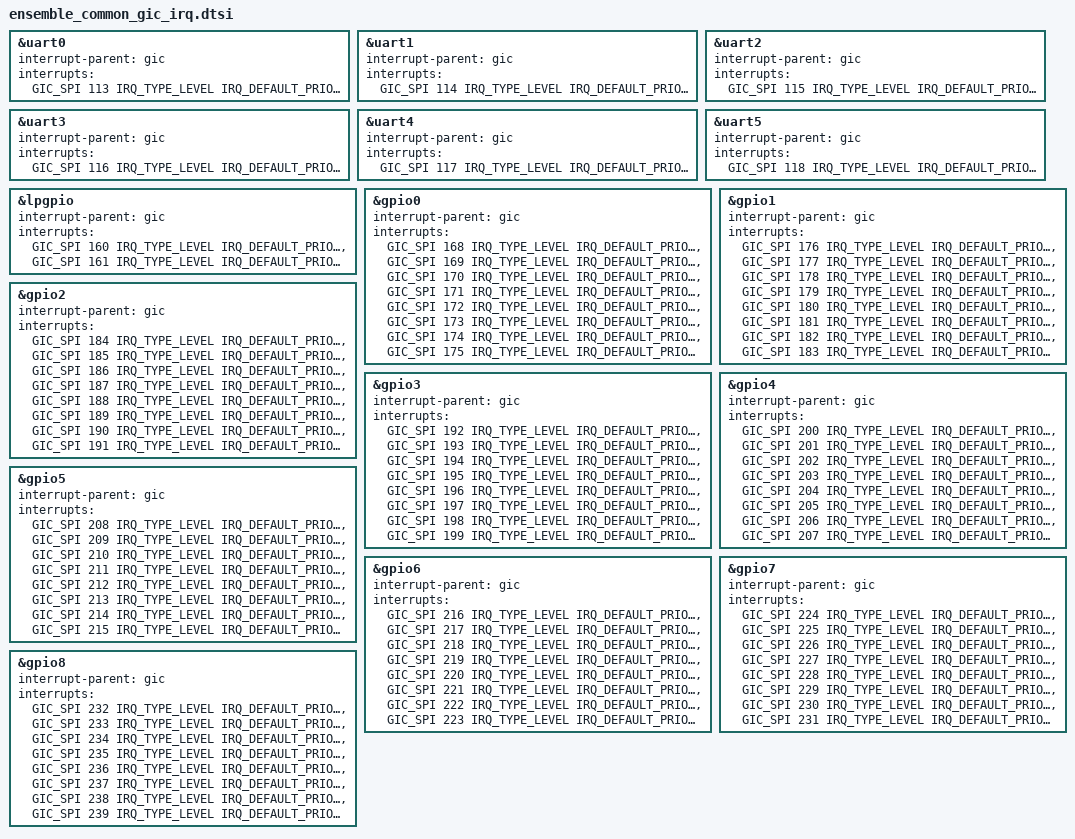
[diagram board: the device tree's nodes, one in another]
/*
 * SPDX-FileCopyrightText: Copyright Alif Semiconductor
 * SPDX-License-Identifier: Apache-2.0
 */

/*
 * GIC interrupt routing for peripherals common to all Ensemble SoCs
 * (the bottom resource layer; see ensemble_common.dtsi). Included by the
 * per-SoC <soc>_gic_irq.dtsi.
 */

#include <zephyr/dt-bindings/interrupt-controller/arm-gic.h>

&uart0 {
	interrupt-parent = <&gic>;
	interrupts = <GIC_SPI 113 IRQ_TYPE_LEVEL IRQ_DEFAULT_PRIORITY>;
};

&uart1 {
	interrupt-parent = <&gic>;
	interrupts = <GIC_SPI 114 IRQ_TYPE_LEVEL IRQ_DEFAULT_PRIORITY>;
};

&uart2 {
	interrupt-parent = <&gic>;
	interrupts = <GIC_SPI 115 IRQ_TYPE_LEVEL IRQ_DEFAULT_PRIORITY>;
};

&uart3 {
	interrupt-parent = <&gic>;
	interrupts = <GIC_SPI 116 IRQ_TYPE_LEVEL IRQ_DEFAULT_PRIORITY>;
};

&uart4 {
	interrupt-parent = <&gic>;
	interrupts = <GIC_SPI 117 IRQ_TYPE_LEVEL IRQ_DEFAULT_PRIORITY>;
};

&uart5 {
	interrupt-parent = <&gic>;
	interrupts = <GIC_SPI 118 IRQ_TYPE_LEVEL IRQ_DEFAULT_PRIORITY>;
};

&lpgpio {
	interrupt-parent = <&gic>;
	interrupts = <GIC_SPI 160 IRQ_TYPE_LEVEL IRQ_DEFAULT_PRIORITY>,
		     <GIC_SPI 161 IRQ_TYPE_LEVEL IRQ_DEFAULT_PRIORITY>;
};

&gpio0 {
	interrupt-parent = <&gic>;
	interrupts = <GIC_SPI 168 IRQ_TYPE_LEVEL IRQ_DEFAULT_PRIORITY>,
		     <GIC_SPI 169 IRQ_TYPE_LEVEL IRQ_DEFAULT_PRIORITY>,
		     <GIC_SPI 170 IRQ_TYPE_LEVEL IRQ_DEFAULT_PRIORITY>,
		     <GIC_SPI 171 IRQ_TYPE_LEVEL IRQ_DEFAULT_PRIORITY>,
		     <GIC_SPI 172 IRQ_TYPE_LEVEL IRQ_DEFAULT_PRIORITY>,
		     <GIC_SPI 173 IRQ_TYPE_LEVEL IRQ_DEFAULT_PRIORITY>,
		     <GIC_SPI 174 IRQ_TYPE_LEVEL IRQ_DEFAULT_PRIORITY>,
		     <GIC_SPI 175 IRQ_TYPE_LEVEL IRQ_DEFAULT_PRIORITY>;
};

&gpio1 {
	interrupt-parent = <&gic>;
	interrupts = <GIC_SPI 176 IRQ_TYPE_LEVEL IRQ_DEFAULT_PRIORITY>,
		     <GIC_SPI 177 IRQ_TYPE_LEVEL IRQ_DEFAULT_PRIORITY>,
		     <GIC_SPI 178 IRQ_TYPE_LEVEL IRQ_DEFAULT_PRIORITY>,
		     <GIC_SPI 179 IRQ_TYPE_LEVEL IRQ_DEFAULT_PRIORITY>,
		     <GIC_SPI 180 IRQ_TYPE_LEVEL IRQ_DEFAULT_PRIORITY>,
		     <GIC_SPI 181 IRQ_TYPE_LEVEL IRQ_DEFAULT_PRIORITY>,
		     <GIC_SPI 182 IRQ_TYPE_LEVEL IRQ_DEFAULT_PRIORITY>,
		     <GIC_SPI 183 IRQ_TYPE_LEVEL IRQ_DEFAULT_PRIORITY>;
};

&gpio2 {
	interrupt-parent = <&gic>;
	interrupts = <GIC_SPI 184 IRQ_TYPE_LEVEL IRQ_DEFAULT_PRIORITY>,
		     <GIC_SPI 185 IRQ_TYPE_LEVEL IRQ_DEFAULT_PRIORITY>,
		     <GIC_SPI 186 IRQ_TYPE_LEVEL IRQ_DEFAULT_PRIORITY>,
		     <GIC_SPI 187 IRQ_TYPE_LEVEL IRQ_DEFAULT_PRIORITY>,
		     <GIC_SPI 188 IRQ_TYPE_LEVEL IRQ_DEFAULT_PRIORITY>,
		     <GIC_SPI 189 IRQ_TYPE_LEVEL IRQ_DEFAULT_PRIORITY>,
		     <GIC_SPI 190 IRQ_TYPE_LEVEL IRQ_DEFAULT_PRIORITY>,
		     <GIC_SPI 191 IRQ_TYPE_LEVEL IRQ_DEFAULT_PRIORITY>;
};

&gpio3 {
	interrupt-parent = <&gic>;
	interrupts = <GIC_SPI 192 IRQ_TYPE_LEVEL IRQ_DEFAULT_PRIORITY>,
		     <GIC_SPI 193 IRQ_TYPE_LEVEL IRQ_DEFAULT_PRIORITY>,
		     <GIC_SPI 194 IRQ_TYPE_LEVEL IRQ_DEFAULT_PRIORITY>,
		     <GIC_SPI 195 IRQ_TYPE_LEVEL IRQ_DEFAULT_PRIORITY>,
		     <GIC_SPI 196 IRQ_TYPE_LEVEL IRQ_DEFAULT_PRIORITY>,
		     <GIC_SPI 197 IRQ_TYPE_LEVEL IRQ_DEFAULT_PRIORITY>,
		     <GIC_SPI 198 IRQ_TYPE_LEVEL IRQ_DEFAULT_PRIORITY>,
		     <GIC_SPI 199 IRQ_TYPE_LEVEL IRQ_DEFAULT_PRIORITY>;
};

&gpio4 {
	interrupt-parent = <&gic>;
	interrupts = <GIC_SPI 200 IRQ_TYPE_LEVEL IRQ_DEFAULT_PRIORITY>,
		     <GIC_SPI 201 IRQ_TYPE_LEVEL IRQ_DEFAULT_PRIORITY>,
		     <GIC_SPI 202 IRQ_TYPE_LEVEL IRQ_DEFAULT_PRIORITY>,
		     <GIC_SPI 203 IRQ_TYPE_LEVEL IRQ_DEFAULT_PRIORITY>,
		     <GIC_SPI 204 IRQ_TYPE_LEVEL IRQ_DEFAULT_PRIORITY>,
		     <GIC_SPI 205 IRQ_TYPE_LEVEL IRQ_DEFAULT_PRIORITY>,
		     <GIC_SPI 206 IRQ_TYPE_LEVEL IRQ_DEFAULT_PRIORITY>,
		     <GIC_SPI 207 IRQ_TYPE_LEVEL IRQ_DEFAULT_PRIORITY>;
};

&gpio5 {
	interrupt-parent = <&gic>;
	interrupts = <GIC_SPI 208 IRQ_TYPE_LEVEL IRQ_DEFAULT_PRIORITY>,
		     <GIC_SPI 209 IRQ_TYPE_LEVEL IRQ_DEFAULT_PRIORITY>,
		     <GIC_SPI 210 IRQ_TYPE_LEVEL IRQ_DEFAULT_PRIORITY>,
		     <GIC_SPI 211 IRQ_TYPE_LEVEL IRQ_DEFAULT_PRIORITY>,
		     <GIC_SPI 212 IRQ_TYPE_LEVEL IRQ_DEFAULT_PRIORITY>,
		     <GIC_SPI 213 IRQ_TYPE_LEVEL IRQ_DEFAULT_PRIORITY>,
		     <GIC_SPI 214 IRQ_TYPE_LEVEL IRQ_DEFAULT_PRIORITY>,
		     <GIC_SPI 215 IRQ_TYPE_LEVEL IRQ_DEFAULT_PRIORITY>;
};

&gpio6 {
	interrupt-parent = <&gic>;
	interrupts = <GIC_SPI 216 IRQ_TYPE_LEVEL IRQ_DEFAULT_PRIORITY>,
		     <GIC_SPI 217 IRQ_TYPE_LEVEL IRQ_DEFAULT_PRIORITY>,
		     <GIC_SPI 218 IRQ_TYPE_LEVEL IRQ_DEFAULT_PRIORITY>,
		     <GIC_SPI 219 IRQ_TYPE_LEVEL IRQ_DEFAULT_PRIORITY>,
		     <GIC_SPI 220 IRQ_TYPE_LEVEL IRQ_DEFAULT_PRIORITY>,
		     <GIC_SPI 221 IRQ_TYPE_LEVEL IRQ_DEFAULT_PRIORITY>,
		     <GIC_SPI 222 IRQ_TYPE_LEVEL IRQ_DEFAULT_PRIORITY>,
		     <GIC_SPI 223 IRQ_TYPE_LEVEL IRQ_DEFAULT_PRIORITY>;
};

&gpio7 {
	interrupt-parent = <&gic>;
	interrupts = <GIC_SPI 224 IRQ_TYPE_LEVEL IRQ_DEFAULT_PRIORITY>,
		     <GIC_SPI 225 IRQ_TYPE_LEVEL IRQ_DEFAULT_PRIORITY>,
		     <GIC_SPI 226 IRQ_TYPE_LEVEL IRQ_DEFAULT_PRIORITY>,
		     <GIC_SPI 227 IRQ_TYPE_LEVEL IRQ_DEFAULT_PRIORITY>,
		     <GIC_SPI 228 IRQ_TYPE_LEVEL IRQ_DEFAULT_PRIORITY>,
		     <GIC_SPI 229 IRQ_TYPE_LEVEL IRQ_DEFAULT_PRIORITY>,
		     <GIC_SPI 230 IRQ_TYPE_LEVEL IRQ_DEFAULT_PRIORITY>,
		     <GIC_SPI 231 IRQ_TYPE_LEVEL IRQ_DEFAULT_PRIORITY>;
};

&gpio8 {
	interrupt-parent = <&gic>;
	interrupts = <GIC_SPI 232 IRQ_TYPE_LEVEL IRQ_DEFAULT_PRIORITY>,
		     <GIC_SPI 233 IRQ_TYPE_LEVEL IRQ_DEFAULT_PRIORITY>,
		     <GIC_SPI 234 IRQ_TYPE_LEVEL IRQ_DEFAULT_PRIORITY>,
		     <GIC_SPI 235 IRQ_TYPE_LEVEL IRQ_DEFAULT_PRIORITY>,
		     <GIC_SPI 236 IRQ_TYPE_LEVEL IRQ_DEFAULT_PRIORITY>,
		     <GIC_SPI 237 IRQ_TYPE_LEVEL IRQ_DEFAULT_PRIORITY>,
		     <GIC_SPI 238 IRQ_TYPE_LEVEL IRQ_DEFAULT_PRIORITY>,
		     <GIC_SPI 239 IRQ_TYPE_LEVEL IRQ_DEFAULT_PRIORITY>;
};
